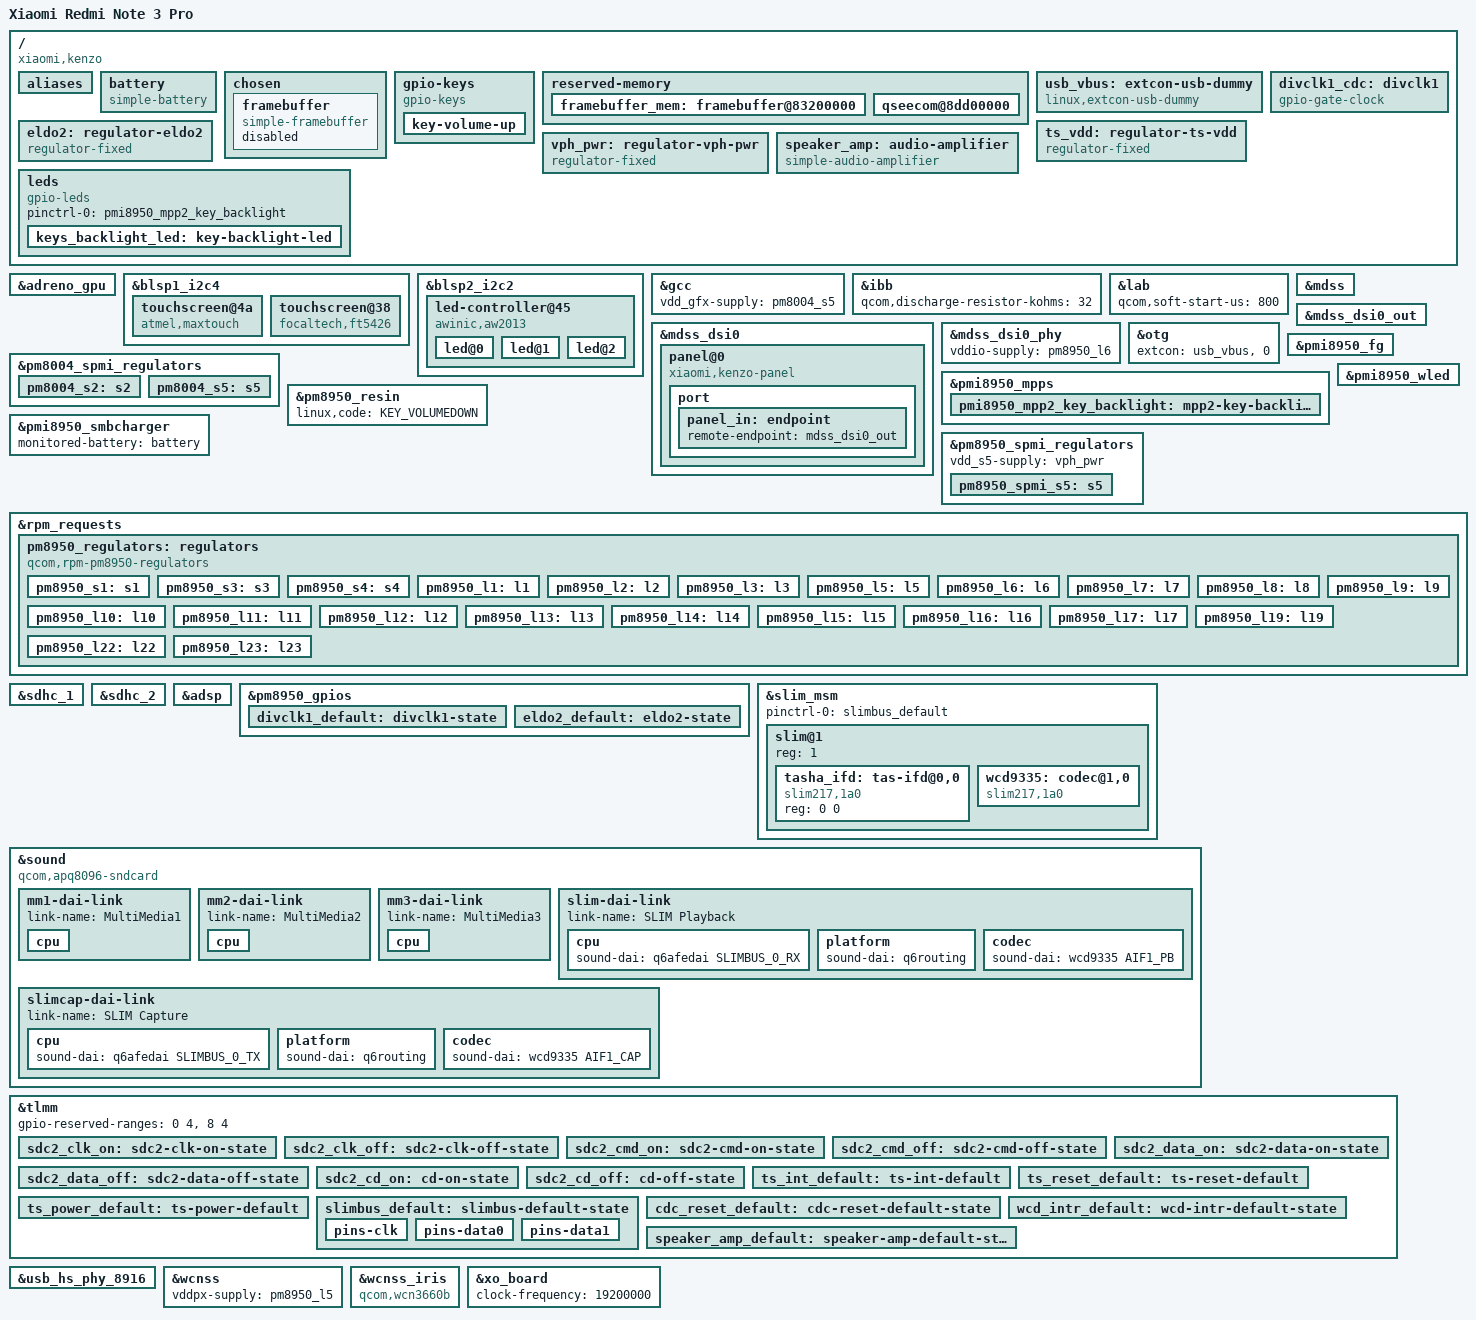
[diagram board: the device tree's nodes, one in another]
// SPDX-License-Identifier: BSD-3-Clause
/*
 * Copyright (c) 2024, Barnabas Czeman <trabarni@gmail.com>
 */
/dts-v1/;

#include <dt-bindings/arm/qcom,ids.h>
#include <dt-bindings/input/atmel-maxtouch.h>
#include <dt-bindings/leds/common.h>
#include <dt-bindings/pinctrl/qcom,pmic-gpio.h>
#include <dt-bindings/sound/qcom,wcd9335.h>

#include "msm8956.dtsi"

#include "pm8004.dtsi"
#include "pm8950.dtsi"
#include "pmi8950.dtsi"

/ {
	model = "Xiaomi Redmi Note 3 Pro";
	compatible = "xiaomi,kenzo", "qcom,msm8956";
	chassis-type = "handset";
	qcom,msm-id = <QCOM_ID_MSM8956 0x10001>;
	qcom,board-id = <QCOM_BOARD_ID_MTP 0>;

	aliases {
		mmc0 = &sdhc_1;
		mmc1 = &sdhc_2;
	};

	battery: battery {
		compatible = "simple-battery";

		charge-full-design-microamp-hours = <4000000>;
		constant-charge-current-max-microamp = <1000000>;
		voltage-min-design-microvolt = <3400000>;
		voltage-max-design-microvolt = <4400000>;
	};

	chosen {
		#address-cells = <2>;
		#size-cells = <2>;
		ranges;

		framebuffer {
			compatible = "simple-framebuffer";
			memory-region = <&framebuffer_mem>;

			width = <1080>;
			height = <1920>;
			stride = <(1080 * 3)>;
			format = "r8g8b8";

			power-domains = <&gcc MDSS_GDSC>;

			clocks = <&gcc GCC_MDSS_AHB_CLK>,
				 <&gcc GCC_MDSS_AXI_CLK>,
				 <&gcc GCC_MDSS_VSYNC_CLK>,
				 <&gcc GCC_MDSS_MDP_CLK>,
				 <&gcc GCC_MDSS_BYTE0_CLK>,
				 <&gcc GCC_MDSS_PCLK0_CLK>,
				 <&gcc GCC_MDSS_ESC0_CLK>;

			status = "disabled";
		};
	};

	gpio-keys {
		compatible = "gpio-keys";

		key-volume-up {
			label = "volume_up";
			linux,code = <KEY_VOLUMEUP>;
			gpios = <&tlmm 113 GPIO_ACTIVE_LOW>;
		};
	};

	reserved-memory {
		framebuffer_mem: framebuffer@83200000 {
			reg = <0x0 0x83200000 0x0 (1920 * 1080 * 3)>;
			no-map;
		};

		/delete-node/ ext-region@85b00000;
		/delete-node/ tz-apps@8dd00000;
		/delete-node/ memory@8da00000;
		qseecom@8dd00000 {
			reg = <0x0 0x8dd00000 0x0 0x1900000>;
			no-map;
		};
	};

	/*usb_id: usb-id {
		compatible = "linux,extcon-usb-gpio";
		id-gpios = <&tlmm 17 GPIO_ACTIVE_HIGH>;
		// pinctrl-0 = <&usb_id_default>;
		// pinctrl-names = "default";
	};*/

	usb_vbus: extcon-usb-dummy {
		compatible = "linux,extcon-usb-dummy";
	};

    ts_vdd: regulator-ts-vdd {
		compatible = "regulator-fixed";
		regulator-name = "ts-vdd";
		enable-active-high;
		gpio = <&tlmm 134 GPIO_ACTIVE_HIGH>;

		regulator-boot-on;
	};

	vph_pwr: regulator-vph-pwr {
		compatible = "regulator-fixed";
		regulator-name = "vph-pwr";
		regulator-always-on;
		regulator-boot-on;
	};

	divclk1_cdc: divclk1 {
		compatible = "gpio-gate-clock";
		clocks = <&rpmcc RPM_SMD_DIV_CLK1>;
		#clock-cells = <0>;
		enable-gpios = <&pm8950_gpios 1 GPIO_ACTIVE_HIGH>;

		pinctrl-names = "default";
		pinctrl-0 = <&divclk1_default>;
	};

	eldo2: regulator-eldo2 {
		compatible = "regulator-fixed";
		regulator-name = "eldo2";
		enable-active-high;
		gpio = <&pm8950_gpios 7 GPIO_ACTIVE_HIGH>;
		regulator-min-microvolt = <1800000>;
		regulator-max-microvolt = <1800000>;
		regulator-always-on;
		regulator-boot-on;

		pinctrl-names = "default";
		pinctrl-0 = <&eldo2_default>;
	};

	speaker_amp: audio-amplifier {
		compatible = "simple-audio-amplifier";
		enable-gpios = <&tlmm 101 GPIO_ACTIVE_HIGH>;
		sound-name-prefix = "Speaker Amp";

		pinctrl-names = "default";
		pinctrl-0 = <&speaker_amp_default>;
	};
};

&adreno_gpu {
	status = "okay";
};

&blsp1_i2c4 {
	status = "okay";

	touchscreen@4a {
		compatible = "atmel,maxtouch";
		reg = <0x4a>;
		interrupt-parent = <&tlmm>;
		interrupts = <65 IRQ_TYPE_EDGE_FALLING>;

		pinctrl-names = "default";
		pinctrl-0 = <&ts_int_default &ts_reset_default &ts_power_default>;

		reset-gpios = <&tlmm 64 GPIO_ACTIVE_LOW>;
		vdda-supply = <&pm8950_l6>;
		vdd-supply = <&ts_vdd>;
	};

	touchscreen@38 {
		compatible = "focaltech,ft5426";
		reg = <0x38>;
		interrupt-parent = <&tlmm>;
		interrupts = <65 IRQ_TYPE_EDGE_FALLING>;

        reset-delay-ms = <20>;
        init-delay-ms = <50>;

		pinctrl-names = "default";
		pinctrl-0 = <&ts_int_default &ts_reset_default &ts_power_default>;

		reset-gpios = <&tlmm 64 GPIO_ACTIVE_LOW>;
		vcc-supply = <&ts_vdd>;
		iovcc-supply = <&pm8950_l6>;

		/*
		 * Panel is 1080x1920. The capacitive keys are extra touch
		 * points below the panel (Y=2100; X=160/540/920) and are
		 * turned into key events by the touchscreen driver itself.
		 * Do not enlarge size-y: Android scales ABS to the display.
		 */
		touchscreen-size-x = <1080>;
		touchscreen-size-y = <1920>;

		/* Left (recents), centre (home), right (back), getevent-measured */
		linux,keycodes = <KEY_APPSELECT>, <KEY_HOMEPAGE>, <KEY_BACK>;
		touch-key-y = <2100>;
		touch-key-height = <96>;

		/* Light the keys backlight while a key is pressed */
		leds = <&keys_backlight_led>;
		/* MIUI keeps the buttons lit for ~5 s after the last press */
		touch-key-led-timeout-ms = <5000>;
	};
};

&blsp2_i2c2 {
	status = "okay";

	/* AW2013 RGB "breath light" notification LED */
	led-controller@45 {
		compatible = "awinic,aw2013";
		reg = <0x45>;

		vcc-supply = <&pm8950_l10>;
		vio-supply = <&pm8950_l5>;

		#address-cells = <1>;
		#size-cells = <0>;

		led@0 {
			reg = <0>;
			color = <LED_COLOR_ID_RED>;
			function = LED_FUNCTION_STATUS;
			led-max-microamp = <5000>;
		};

		led@1 {
			reg = <1>;
			color = <LED_COLOR_ID_GREEN>;
			function = LED_FUNCTION_STATUS;
			led-max-microamp = <5000>;
		};

		led@2 {
			reg = <2>;
			color = <LED_COLOR_ID_BLUE>;
			function = LED_FUNCTION_STATUS;
			led-max-microamp = <5000>;
		};
	};
};

&gcc {
	vdd_gfx-supply = <&pm8004_s5>;
};

&ibb {
	qcom,discharge-resistor-kohms = <32>;
};

&lab {
	qcom,soft-start-us = <800>;
};

&mdss {
	status = "okay";
};

&mdss_dsi0 {
	vdd-supply = <&pm8950_l17>;
	vdda-supply = <&pm8950_l1>;
	vddio-supply = <&pm8950_l6>;

	status = "okay";

	panel@0 {
		compatible = "xiaomi,kenzo-panel";
		reg = <0>;

		reset-gpios = <&tlmm 25 GPIO_ACTIVE_LOW>;
		backlight = <&pmi8950_wled>;

		vsp-supply = <&lab>;
		vsn-supply = <&ibb>;

		port {
			panel_in: endpoint {
				remote-endpoint = <&mdss_dsi0_out>;
			};
		};
	};
};

&mdss_dsi0_out {
	data-lanes = <0 1 2 3>;
	remote-endpoint = <&panel_in>;
};

&mdss_dsi0_phy {
	vddio-supply = <&pm8950_l6>;
	status = "okay";
};

&otg {
	extcon = <&usb_vbus>, <0>;
	status = "okay";
};

&pm8004_spmi_regulators {
	vdd_s2-supply = <&vph_pwr>;
	vdd_s5-supply = <&vph_pwr>;

	/* Cluster 1 supply */
	pm8004_s2: s2 {
		/* regulator-min-microvolt = <500000>; */
		/* Set .95V to prevent unstabilities until CPR for this SoC is done */
		regulator-min-microvolt = <950000>;
		regulator-max-microvolt = <1165000>;
		regulator-name = "vdd_apc1";
		/* Set always on until the CPU PLL is done */
		regulator-always-on;
		regulator-boot-on;
	};

	pm8004_s5: s5 {
		regulator-min-microvolt = <950000>;
		regulator-max-microvolt = <1165000>;
		regulator-enable-ramp-delay = <500>;
		regulator-name = "vdd_gfx";
		/* Hack this on until the gpu driver is ready for it */
		regulator-always-on;
	};
};

&pmi8950_fg {
	monitored-battery = <&battery>;
	power-supplies = <&pmi8950_smbcharger>;
	status = "okay";
};

&pmi8950_mpps {
	pmi8950_mpp2_key_backlight: mpp2-key-backlight-state {
		pins = "mpp2";
		function = "sink";

		/*
		 * Current sink driving the capacitive keys backlight LEDs,
		 * 5 mA on/off (the downstream "manual" LED mode on MPP2).
		 */
		drive-strength = <5>;
		output-low;
	};
};

/ {
	leds {
		compatible = "gpio-leds";

		pinctrl-names = "default";
		pinctrl-0 = <&pmi8950_mpp2_key_backlight>;

		keys_backlight_led: key-backlight-led {
			function = LED_FUNCTION_KBD_BACKLIGHT;
			color = <LED_COLOR_ID_WHITE>;
			/* SPMI-MPP GPIO specifiers use 1-based physical pin numbers: 2 = MPP2 */
			gpios = <&pmi8950_mpps 2 GPIO_ACTIVE_HIGH>;
		};
	};
};

&pm8950_resin {
	linux,code = <KEY_VOLUMEDOWN>;
	status = "okay";
};

&pmi8950_smbcharger {
	monitored-battery = <&battery>;
	status = "okay";
};

&pm8950_spmi_regulators {
	vdd_s5-supply = <&vph_pwr>;

	/* Cluster 0 supply */
	pm8950_spmi_s5: s5 {
		/* Set .95V to prevent unstabilities until CPR for this SoC is done */
		/* regulator-min-microvolt = <500000>; */
		regulator-min-microvolt = <950000>;
		regulator-max-microvolt = <1165000>;
		regulator-name = "vdd_apc0";
		/* Set always on until the CPU PLL is done */
		regulator-always-on;
		regulator-boot-on;
	};
};

&pmi8950_wled {
	qcom,current-limit-microamp = <20000>;
	qcom,ovp-millivolt = <29500>;
	qcom,num-strings = <2>;
	qcom,external-pfet;

	status = "okay";
};

&rpm_requests {
	pm8950_regulators: regulators {
		compatible = "qcom,rpm-pm8950-regulators";

		vdd_s1-supply = <&vph_pwr>;
		vdd_s2-supply = <&vph_pwr>;
		vdd_s3-supply = <&vph_pwr>;
		vdd_s4-supply = <&vph_pwr>;
		vdd_s6-supply = <&vph_pwr>;
		vdd_l1_l19-supply = <&pm8950_s3>;
		vdd_l2_l23-supply = <&pm8950_s3>;
		vdd_l3-supply = <&pm8950_s3>;
		vdd_l5_l6_l7_l16-supply = <&pm8950_s4>;
		vdd_l8_l11_l12_l17_l22-supply = <&vph_pwr>;

		pm8950_s1: s1 {
			regulator-min-microvolt = <1000000>;
			regulator-max-microvolt = <1162500>;
		};

		pm8950_s3: s3 {
			regulator-min-microvolt = <1325000>;
			regulator-max-microvolt = <1325000>;
		};

		pm8950_s4: s4 {
			regulator-min-microvolt = <2050000>;
			regulator-max-microvolt = <2050000>;
		};

		pm8950_l1: l1 {
			regulator-min-microvolt = <1200000>;
			regulator-max-microvolt = <1200000>;
		};

		pm8950_l2: l2 {
			regulator-min-microvolt = <1200000>;
			regulator-max-microvolt = <1200000>;
		};

		pm8950_l3: l3 {
			regulator-min-microvolt = <1000000>;
			regulator-max-microvolt = <1100000>;
		};

		pm8950_l5: l5 {
			regulator-min-microvolt = <1800000>;
			regulator-max-microvolt = <1800000>;
		};

		pm8950_l6: l6 {
			regulator-min-microvolt = <1800000>;
			regulator-max-microvolt = <1800000>;
		};

		pm8950_l7: l7 {
			regulator-min-microvolt = <1800000>;
			regulator-max-microvolt = <1800000>;
		};

		pm8950_l8: l8 {
			regulator-min-microvolt = <2900000>;
			regulator-max-microvolt = <2900000>;
		};

		pm8950_l9: l9 {
			regulator-min-microvolt = <3000000>;
			regulator-max-microvolt = <3300000>;
		};

		pm8950_l10: l10 {
			regulator-min-microvolt = <2800000>;
			regulator-max-microvolt = <2800000>;
		};

		pm8950_l11: l11 {
			regulator-min-microvolt = <2950000>;
			regulator-max-microvolt = <2950000>;
		};

		pm8950_l12: l12 {
			regulator-min-microvolt = <1800000>;
			regulator-max-microvolt = <2950000>;
		};

		pm8950_l13: l13 {
			regulator-min-microvolt = <3075000>;
			regulator-max-microvolt = <3075000>;
		};

		pm8950_l14: l14 {
			regulator-min-microvolt = <1800000>;
			regulator-max-microvolt = <3300000>;
		};

		pm8950_l15: l15 {
			regulator-min-microvolt = <1800000>;
			regulator-max-microvolt = <3300000>;
		};

		pm8950_l16: l16 {
			regulator-min-microvolt = <1800000>;
			regulator-max-microvolt = <1800000>;
		};

		pm8950_l17: l17 {
			regulator-min-microvolt = <2850000>;
			regulator-max-microvolt = <2850000>;
		};

		pm8950_l19: l19 {
			regulator-min-microvolt = <1200000>;
			regulator-max-microvolt = <1350000>;
		};

		pm8950_l22: l22 {
			regulator-min-microvolt = <2800000>;
			regulator-max-microvolt = <2950000>;
		};

		pm8950_l23: l23 {
			regulator-min-microvolt = <1200000>;
			regulator-max-microvolt = <1200000>;
		};
	};
};


&sdhc_1 {
	vmmc-supply = <&pm8950_l8>;
	vqmmc-supply = <&pm8950_l5>;
	non-removable;

	status = "okay";
};

&sdhc_2 {
	cd-gpios = <&tlmm 100 GPIO_ACTIVE_LOW>;
	vmmc-supply = <&pm8950_l11>;
	vqmmc-supply = <&pm8950_l12>;

	pinctrl-0 = <&sdc2_clk_on &sdc2_cmd_on &sdc2_data_on &sdc2_cd_on>;
	pinctrl-1 = <&sdc2_clk_off &sdc2_cmd_off &sdc2_data_off &sdc2_cd_off>;
	pinctrl-names = "default", "sleep";

	status = "okay";
};

&adsp {
	status = "okay";
};

&pm8950_gpios {
	divclk1_default: divclk1-state {
		pins = "gpio1";
		function = "func2";
		bias-disable;
		power-source = <2>;
	};

	eldo2_default: eldo2-state {
		pins = "gpio7";
		function = "normal";
		bias-disable;
		power-source = <0>;
	};
};

&slim_msm {
	pinctrl-names = "default";
	pinctrl-0 = <&slimbus_default>;
	status = "okay";

	slim@1 {
		reg = <1>;
		#address-cells = <2>;
		#size-cells = <0>;

		tasha_ifd: tas-ifd@0,0 {
			compatible = "slim217,1a0";
			reg = <0 0>;
		};

		wcd9335: codec@1,0 {
			compatible = "slim217,1a0";
			reg = <1 0>;

			clock-names = "mclk", "slimbus";
			clocks = <&divclk1_cdc>,
				 <&rpmcc RPM_SMD_BB_CLK1>;
			interrupt-parent = <&tlmm>;
			interrupts = <120 IRQ_TYPE_LEVEL_HIGH>;
			interrupt-names = "intr1";
			interrupt-controller;
			#interrupt-cells = <1>;

			pinctrl-0 = <&cdc_reset_default &wcd_intr_default>;
			pinctrl-names = "default";

			reset-gpios = <&tlmm 133 GPIO_ACTIVE_LOW>;
			slim-ifc-dev = <&tasha_ifd>;

			#sound-dai-cells = <1>;

			vdd-buck-supply = <&eldo2>;
			vdd-buck-sido-supply = <&eldo2>;
			vdd-rx-supply = <&pm8950_l5>;
			vdd-tx-supply = <&pm8950_l5>;
			vdd-vbat-supply = <&vph_pwr>;
			vdd-io-supply = <&pm8950_l5>;
		};
	};
};

&sound {
	compatible = "qcom,apq8096-sndcard";
	model = "xiaomi-kenzo";

	audio-routing =
		"RX_BIAS", "MCLK",
		"Speaker Amp INL", "LINEOUT4",
		"Speaker", "Speaker Amp OUTL",
		"AMIC1", "MIC BIAS1",
		"MIC BIAS1", "Handset Mic",
		"AMIC2", "MIC BIAS2",
		"MIC BIAS2", "Headset Mic",
		"AMIC3", "MIC BIAS3",
		"MIC BIAS3", "Secondary Mic";

	aux-devs = <&speaker_amp>;

	widgets =
		"Speaker", "Speaker",
		"Mic", "Handset Mic",
		"Mic", "Headset Mic",
		"Mic", "Secondary Mic";
	pin-switches = "Speaker";

	status = "okay";

	mm1-dai-link {
		link-name = "MultiMedia1";
		cpu {
			sound-dai = <&q6asmdai MSM_FRONTEND_DAI_MULTIMEDIA1>;
		};
	};

	mm2-dai-link {
		link-name = "MultiMedia2";
		cpu {
			sound-dai = <&q6asmdai MSM_FRONTEND_DAI_MULTIMEDIA2>;
		};
	};

	mm3-dai-link {
		link-name = "MultiMedia3";
		cpu {
			sound-dai = <&q6asmdai MSM_FRONTEND_DAI_MULTIMEDIA3>;
		};
	};

	slim-dai-link {
		link-name = "SLIM Playback";
		cpu {
			sound-dai = <&q6afedai SLIMBUS_0_RX>;
		};

		platform {
			sound-dai = <&q6routing>;
		};

		codec {
			sound-dai = <&wcd9335 AIF1_PB>;
		};
	};

	slimcap-dai-link {
		link-name = "SLIM Capture";
		cpu {
			sound-dai = <&q6afedai SLIMBUS_0_TX>;
		};

		platform {
			sound-dai = <&q6routing>;
		};

		codec {
			sound-dai = <&wcd9335 AIF1_CAP>;
		};
	};
};

&tlmm {
	gpio-reserved-ranges = <0 4>, <8 4>;

	sdc2_clk_on: sdc2-clk-on-state {
		pins = "sdc2_clk";
		drive-strength = <16>;
		bias-disable;
	};

	sdc2_clk_off: sdc2-clk-off-state {
		pins = "sdc2_clk";
		bias-disable;
		drive-strength = <2>;
	};

	sdc2_cmd_on: sdc2-cmd-on-state {
		pins = "sdc2_cmd";
		bias-pull-up;
		drive-strength = <10>;
	};

	sdc2_cmd_off: sdc2-cmd-off-state {
		pins = "sdc2_cmd";
		bias-pull-up;
		drive-strength = <2>;
	};

	sdc2_data_on: sdc2-data-on-state {
		pins = "sdc2_data";
		bias-pull-up;
		drive-strength = <10>;
	};

	sdc2_data_off: sdc2-data-off-state {
		pins = "sdc2_data";
		bias-pull-up;
		drive-strength = <2>;
	};

	sdc2_cd_on: cd-on-state {
		pins = "gpio100";
		function = "gpio";
		drive-strength = <2>;
		bias-pull-up;
	};

	sdc2_cd_off: cd-off-state {
		pins = "gpio100";
		function = "gpio";
		drive-strength = <2>;
		bias-disable;
	};

	ts_int_default: ts-int-default {
		pins = "gpio65";
		function = "gpio";
		drive-strength = <8>;
		bias-pull-up;
	};

	ts_reset_default: ts-reset-default {
		pins = "gpio64";
		function = "gpio";
		drive-strength = <8>;
		bias-pull-up;
	};

	ts_power_default: ts-power-default {
		pins = "gpio134";
		function = "gpio";
		drive-strength = <16>;
		bias-pull-up;
	};

	slimbus_default: slimbus-default-state {
		pins-clk {
			pins = "gpio117";
			function = "lpass_slimbus";
			drive-strength = <8>;
			bias-disable;
		};

		pins-data0 {
			pins = "gpio118";
			function = "lpass_slimbus0";
			drive-strength = <8>;
			bias-disable;
		};

		pins-data1 {
			pins = "gpio119";
			function = "lpass_slimbus1";
			drive-strength = <8>;
			bias-disable;
		};
	};

	cdc_reset_default: cdc-reset-default-state {
		pins = "gpio133";
		function = "gpio";
		drive-strength = <16>;
		bias-pull-down;
	};

	wcd_intr_default: wcd-intr-default-state {
		pins = "gpio120";
		function = "gpio";
		drive-strength = <2>;
		bias-pull-down;
	};

	speaker_amp_default: speaker-amp-default-state {
		pins = "gpio101";
		function = "gpio";
		drive-strength = <2>;
		bias-pull-down;
	};
};

&usb_hs_phy_8916 {
	v1p8-supply = <&pm8950_l7>;
	v3p3-supply = <&pm8950_l13>;
	extcon = <&usb_vbus>;
	status = "okay";
};


&wcnss {
	vddpx-supply = <&pm8950_l5>;
	status = "okay";
};

&wcnss_iris {
	compatible = "qcom,wcn3660b";
	vddxo-supply = <&pm8950_l7>;
	vddrfa-supply = <&pm8950_l19>;
	vddpa-supply = <&pm8950_l9>;
	vdddig-supply = <&pm8950_l5>;
	status = "okay";
};

&xo_board {
	clock-frequency = <19200000>;
};
